# psc3m6 register map
Vendor: Infineon Technologies; Series: PSC3M6; File version: 1.0
CPU: CM33 r0p1, little endian, MPU, FPU, DSP, VTOR, 3 interrupt priority bits, 167 interrupts
Registers are 32-bit, read-write, reset 0x0 unless marked. A register's access mark holds for its fields unless they carry their own. Offsets are from the block's base; [hi:lo] are bit positions; lines under a group give offsets from that group; {n}, {i} and the like mark numbered series; 'fields as' and 'values as' point back to an identical list; <NAME> marks a mode.

## HPPASS (part 3 of 3) — Top Level of MCPASS IP
Base 0x42B00000
0xB0000 CSG group — Comparator Slope Generator
  {0x0+0x40*j} SLICE[{j}] (j=0..8) group — CSG Slice configuration registers
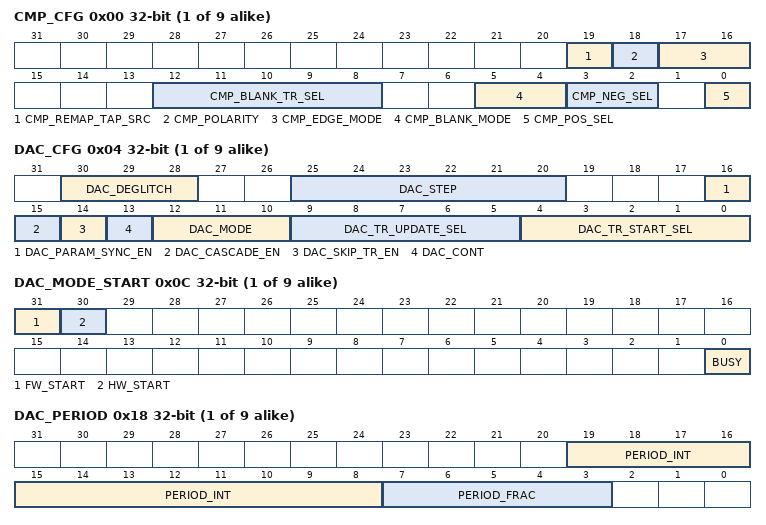
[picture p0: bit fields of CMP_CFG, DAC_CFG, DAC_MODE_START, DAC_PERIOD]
    0x00 CMP_CFG — Comparator Control Register
      [19] CMP_REMAP_TAP_SRC — Choose where to Tap the Remap Source 0: After Glitch Filter 1: After DAC Blanking
      [18] CMP_POLARITY — Comparator Polarity
        0=True (Comparator output is not inverted); 1=INV (Comparator output is inverted)
      [17:16] CMP_EDGE_MODE — Comparator signal mode for Interrupt generation and AC status
        0=DISABLE (Disabled, no interrupts will be asserted); 1=RISING (Rising edge); 2=FALLING (Falling edge); 3=BOTH (Both rising and falling edges)
      [12:8] CMP_BLANK_TR_SEL — Comparator Blank Trigger Select. Select one of the available input MCPASS HW/FW LEVEL mode triggers.
        0=DISABLED (N/A); {v}=TR{v-1} (N/A) (v=1..16)
      [5:4] CMP_BLANK_MODE — Comparator Blanking Mode. Select a level input trigger from CMP_BLANK_TR_SEL to gate the comparators output of this slice to 0. Polarity of active signal is selectable.
        0=DISABLED (Comparator output is not gated. Edge based blanking is enabled. Please see CSG_GROUP_CFG for more information on Edge Based Blanking.); 1=GATE_ON_ONE (Comparator output is gated to 0 by a '1' level trigger. Edge based blanking is disabled.); 2=GATE_ON_ZERO (Comparator output is gated to 0 by a '0' level trigger. Edge based blanking is disabled.)
      [3:2] CMP_NEG_SEL — Comparator Negative Input Select (Select positive input from CMP_POS_SEL)
        0=DAC (DAC is negative input); 1=RSVD_1 (N/A); 2=AIN_NA (Analog input NA); 3=AIN_NB (Analog input NB)
      [0] CMP_POS_SEL — Comparator Positive Input Select (Select negative input from CMP_NEG_SEL)
        0=AIN_PA (Analog input PA); 1=AIN_PB (Analog input PB AN_B[0] etc)
    0x04 DAC_CFG — DAC Control Register
      [30:28] DAC_DEGLITCH — DAC Deglitch Configuration. Default is disabled. If enabled, on any DAC value update,the CMP output is latched in it's current state for the number of cycles indicated.
        0=DISABLED (N/A); 1=ONE_CYCLE (N/A); 2=TWO_CYCLES (N/A); 3=THREE_CYCLES (N/A); 4=FOUR_CYCLES (N/A); 5=FIVE_CYCLES (N/A); 6=SIX_CYCLES (N/A); 7=SEVEN_CYCLES (N/A)
      [25:20] DAC_STEP — Static value of 6 bit DAC step size. Step size is DAC_STEP +1 (default is '1') , range is 1 - 64, only valid in SLOPE/LUT modes. NOTE: In LUT mode each step jumps to a new LUT value on WORD boundaries. So for example: DAC_STEP = 0 (default Step size of 1) advances the LUT address by 4 (LUT WORD boundary) DAC_STEP = 1 (Step size of 2) advances the LUT address by 8, etc
      [16] DAC_PARAM_SYNC_EN — Parameter Sync Enable. 0: Disabled. Always update parameters on DAC trigger (as defined by DAC_MODE) 1: Enabled. Only update parameters on DAC trigger if DAC_PARAM_SYNC.READY is set.
      [15] DAC_CASCADE_EN — Cascade Enable. Synchronize parameter update with previous CSG slice in the case of multi-phase operation. 0: Disabled. 1: Enabled. This CSG updates it's parameters on a DAC trigger only after the previous numbered CSG has updated it's parameters.
      [14] DAC_SKIP_TR_EN — Skip the first DAC hardware update trigger afer a mode is enabled. Allows for a minimum of a full trigger period before the first hardware update occurs. This bit should only be set before operations begin. It should remain set during operation as well. 0: First trigger following DAC_MODE_EN updates the DAC value. 1: First trigger following DAC_MODE_EN is skipped. Following trigger updates the DAC value.
      [13] DAC_CONT — DAC Continuous Mode (Only valid for Slope and LUT modes) 0: Slope/LUT operation is One-Shot, last output value is held 1: Slope/LUT operation is Continuous, operation is restarted when end value is reached
      [12:10] DAC_MODE — DAC Operating Mode. This setting may only be changed when the mode is disabled. See DAC_MODE_START.
        0=BUFFERED (Single Value Buffered Mode); 1=HYSTERETIC (Two Value Hysteretic Buffered Mode); 2=SLOPE_RISING (Rising Slope Mode); 3=SLOPE_FALLING (Falling Slope Mode); 4=SLOPE_TRIANGULAR (Triangular Slope Mode); 5=LUT_FORWARD (LUT Forward Mode); 6=LUT_REVERSE (LUT Reverse Mode); 7=LUT_FWD_REV (LUT Forward Reverse Mode)
      [9:5] DAC_TR_UPDATE_SEL — DAC Trigger Update Select. Select one of the triggers or internal events. See DAC_MODE for detailed operation. If one of the MCPASS HW or FW triggers are selected (see INFRA), then the trigger must be PULSE mode. In addition, the maximum frequency of the active trigger edge must be less than or equal to CSG CLOCK/2 (every other clock).
        0=DISABLED (N/A); 1=TR0 (HW (or FW) input triggers); {v}=TR{v-1} (N/A) (v=2..8); 9=TR8 (HW (or FW) input triggers); {v}=TR{v-1} (N/A) (v=10..16); 17=AC (AC trigger); 18=DAC_PERIOD_TC (Period terminal count. Period divider value is programmed in DAC_PERIOD register); 19=CMP_LEVEL (Use comparator output as Update Trigger: (Used only in Hysteretic Mode ) With DAC_VAL_A as high threshold and DAC_VAL_B as low threshold, CMP 0 to 1 transition (voltage high) outputs DAC_VAL_B ...); 20=CMP_LEVEL_INV (Use inverted comparator output as Update Trigger (Used only in Hysteretic Mode ) (e.g. in the case CMP_POLARITY is set))
      [4:0] DAC_TR_START_SEL — DAC Trigger Start Select. Select one of the MCPASS HW or FW triggers. Trigger must be PULSE mode (see INFRA). See DAC_MODE_START register to select this as the DAC start trigger.
        0=DISABLED (N/A); 1=TR0 (HW (or FW) input triggers); {v}=TR{v-1} (N/A) (v=2..16); 17=AC (AC trigger)
    0x08 DAC_PARAM_SYNC — DAC Parameter Synchronized Update
      [0] READY write-1-sets — Use this bit to synchronize the update of multiple DAC parameters. If DAC_PARAM_SYNC_EN bit is '1', then set this bit after writes to all parameter registers (VAL_A, VAL_B, DAC_PERIOD, DAC_STEP) are complete to synchronize parameter update on a subsequent DAC trigger This allows for writes to multiple registers to be written before new parameters are updated to avoid partial updates. This bit is cleared by HW on the parameter update event. if DAC_PARAM_SYNC_EN is '0', this bit is ignored and parameters are updated on the following UPDATE trigger. NOTE: This bit can be used in conjunction with DAC_CASCADE_EN to synchronize the parameter update of multiple CSG slices.
    0x0C DAC_MODE_START
      [31] FW_START — 1: Starts the selected mode on this FW write. 0: Stops the selected mode. When this bit is cleared, the current DAC_VAL will not change unless it is over-written directly - or a new DAC mode is started. This field is automatically reset to '0' on DAC_SLOPE_DONE event (unless DAC_CONT is set for continous mode).
      [30] HW_START — 1: Wait for subsequent DAC_START_TR to start the selected mode. 0: Stops the selected mode. When this bit is cleared, the current DAC_VAL will not change unless it is over-written directly - or a new DAC mode is started. This field is automatically reset to '0' on DAC_SLOPE_DONE event (unless DAC_CONT is set for continous mode).
      [0] BUSY ro — Read only bit to indicate that a DAC MODE has been enabled and is currently in progress. If FW_START is used to start the mode, then the FW_START bit is equivalent to this bit and low when the mode is completed or stopped. If HW_START is used to start the mode, then this status bit goes high on the DAC_START_TR event, and low when the mode is completed or stopped. NOTE: This read only bit refects the state of the DAC controller which is reset in DeepSleep and therefore this bit is not a retention bit.
    0x10 DAC_VAL_A — DAC Vaue A Buffer
      [9:0] VALUE — DAC A Value, usage is mode dependent (see DAC_MODE) NOTE: In LUT modes this is the Start Address of the LUT waveform in byte address format (e.g. 0, 4, 8, ... 1F8, 1FC)
    0x14 DAC_VAL_B — DAC Value B Buffer
      [9:0] VALUE — DAC B Value, usage is mode dependent (see DAC_MODE) NOTE: In LUT modes this is the End Address of the LUT waveform in byte address format (e.g. 0, 4, 8, ... 1F8, 1FC)
    0x18 DAC_PERIOD — DAC Period Buffer
      [19:8] PERIOD_INT — 12-bit Integer Divide Value. Integer count by (1+PERIOD_INT). Allows for integer counts in the range [1, 4096].
      [7:3] PERIOD_FRAC — 5-bit Fractional Divide Value. Allows for fractional count in the range [0, 31/32]
    0x1C DAC_VAL — DAC FW write
      [9:0] VALUE — Direct drive to DAC Hard IP for output. When DAC_MODE_EN is '0', the value in this register is output. A write to this register also STOPs the current DAC_MODE operation, and subsequent DAC triggers are ignored.
    0x20 DAC_STATUS ro — Read of Current DAC Value
      [9:0] DAC_VAL — Read Only value of current digital DAC output
    0x24 CMP_STATUS ro — Read of Comparator Value
      [0] CMP_VAL — Read Only value of comparator output
  {0x400+0x200*j} LUT_CFG[{j}] (j=0..2) group — DAC LUT waveform data
    {0x0+4k} LUT_DATA[{k}] (k=0..127) reset not defined — LUT Waveform Data
      [9:0] DATA — DAC waveform
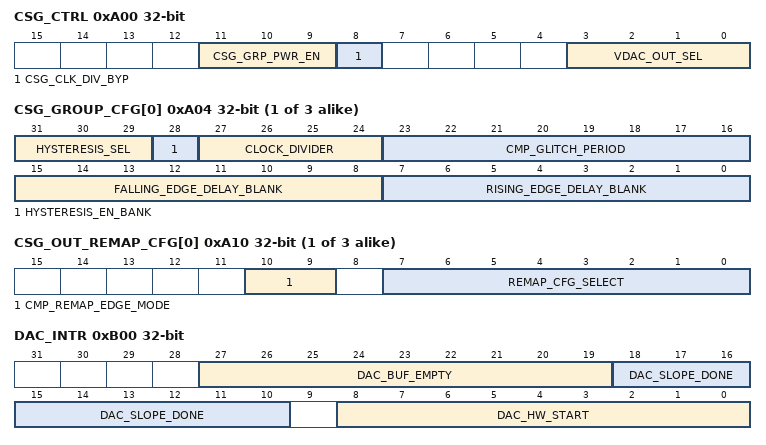
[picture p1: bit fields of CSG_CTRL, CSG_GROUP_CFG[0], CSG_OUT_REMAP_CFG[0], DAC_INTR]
  0xA00 CSG_CTRL — CSG control register
    [11:9] CSG_GRP_PWR_EN — Individual Group Power Enables. 0: Slices 0-2 1: Slices 3-5 2: Slices 6-8
    [8] CSG_CLK_DIV_BYP
    [3:0] VDAC_OUT_SEL — Select the DAC output for SAR conversion
      0=DISABLED (Hi-Z (Disabled)); {v}=DAC{v-1} (Connect DAC{v-1} to ADC input) (v=1..9)
  {0xA04+4j} CSG_GROUP_CFG[{j}] (j=0..2) — CSG Group Configuration Register
    [31:29] HYSTERESIS_SEL — Hysteresis magnitude selection
      0=HYST_0MV (0 mV); 1=HYST_12MV (12 mV); 2=HYST_24MV (24 mV); 3=HYST_36MV (36 mV); 4=HYST_48MV (48 mV); 5=HYST_60MV (60 mV); 6=HYST_72MV (72 mV); 7=HYST_84MV (84mV)
    [28] HYSTERESIS_EN_BANK — Enable the Hysteresis in Bank of CSGs 0x0 - disabled Hysteresis 0x1 - enable Hysteresis
    [27:24] CLOCK_DIVIDER — Comparator Blank Clock Divider. To add more range to the blanking period, the clock can be divided.
      0=DIV_1 (N/A); 1=DIV_2 (N/A); 2=DIV_4 (N/A); 3=DIV_8 (N/A); 4=DIV_16 (N/A); 5=DIV_32 (N/A); 6=DIV_64 (N/A); 7=DIV_128 (N/A); 8=DIV_256 (N/A); 9=DIV_512 (N/A); 10=DIV_1024 (N/A); 11=DIV_2048 (N/A)
    [23:16] CMP_GLITCH_PERIOD — Comparator Glitch Width Count. Choose the number of output values equal to 0x1 in series to achieve an output filter of 0x1. This number also reflects the number of output value equal to 0x0 in series to achieve a an output filter of 0x0.
    [15:8] FALLING_EDGE_DELAY_BLANK — Comparator Blank Clock Period. Choose the number of clock periods to blank starting at the negative edge of the Level Trigger. This is scaled by the Comparator Blank Clock Divider. 0 - 255 - Clock Period selection
    [7:0] RISING_EDGE_DELAY_BLANK — Comparator Blank Clock Period. Choose the number of clock periods to blank starting at the positive edge of the Level Trigger. This is scaled by the Comparator Blank Clock Divider. 0 - 255 - Clock Period selection
  {0xA10+4j} CSG_OUT_REMAP_CFG[{j}] (j=0..2) — CSG Output Remap Configuration
    [10:9] CMP_REMAP_EDGE_MODE — Comparator signal mode for Interrupt generation and AC status
      0=DISABLE (edge detection disabled. Interrupt disabled); 1=RISING (Rising edge); 2=FALLING (Falling edge); 3=BOTH (Both rising and falling edges)
    [7:0] REMAP_CFG_SELECT — Remap CSG Output Logical Translation. The CSG Comparator outputs act as the control bits of an 8:1 mux. This field is the 8 bits.
  0xB00 DAC_INTR — DAC Interrupt register
    [27:19] DAC_BUF_EMPTY write-1-clears — When BUFFERED or HYSTERETIC mode is enabled, this interrupt is set when there is a DAC UPDATE trigger that transfers the buffered value(s) to active value(s) (see mode operation) and it means that the user may write new values to the buffer registers.
    [18:10] DAC_SLOPE_DONE write-1-clears — When SLOPE or LUT mode is enabled, this interrupt is set when the SLOPE (or LUT waveform) has completed. This interrupt is also set periodically on the last value of a DAC SLOPE in continuous mode
    [8:0] DAC_HW_START write-1-clears — This DAC_MODE operation was started with a HW START trigger.
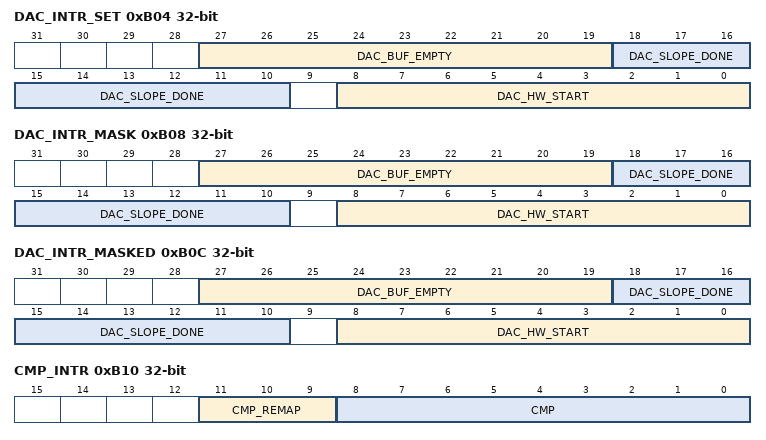
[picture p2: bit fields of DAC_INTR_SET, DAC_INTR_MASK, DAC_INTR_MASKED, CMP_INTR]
  0xB04 DAC_INTR_SET — DAC Interrupt request set register
    [27:19] DAC_BUF_EMPTY write-1-sets — Write with '1' to set corresponding bit in interrupt request register.
    [18:10] DAC_SLOPE_DONE write-1-sets — Write with '1' to set corresponding bit in interrupt request register.
    [8:0] DAC_HW_START write-1-sets — Write with '1' to set corresponding bit in interrupt request register.
  0xB08 DAC_INTR_MASK — DAC Interrupt request mask
    [27:19] DAC_BUF_EMPTY — Mask bit for corresponding bit in interrupt request register.
    [18:10] DAC_SLOPE_DONE — Mask bit for corresponding bit in interrupt request register.
    [8:0] DAC_HW_START — Mask bit for corresponding bit in interrupt request register.
  0xB0C DAC_INTR_MASKED ro — DAC Interrupt request masked
    [27:19] DAC_BUF_EMPTY — Logical and of corresponding request and mask bits.
    [18:10] DAC_SLOPE_DONE — Logical and of corresponding request and mask bits.
    [8:0] DAC_HW_START — Logical and of corresponding request and mask bits.
  0xB10 CMP_INTR — CMP Interrupt register
    [11:9] CMP_REMAP write-1-clears — This CMP_REMAP(n) state has generated an interrupt request (see CSG_SLICE.CSG_OUT_REMAP_CFG.CMP_REMAP_EDGE_MODE)
    [8:0] CMP write-1-clears — This CMP(n) state has generated an interrupt request (see CSG_SLICE.CMP_CFG.CMP_EDGE_MODE)
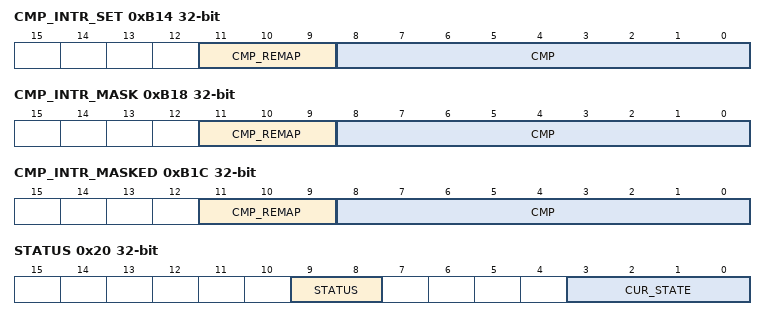
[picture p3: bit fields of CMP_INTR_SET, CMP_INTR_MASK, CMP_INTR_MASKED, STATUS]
  0xB14 CMP_INTR_SET — CMP Interrupt request set register
    [11:9] CMP_REMAP write-1-sets — Write with '1' to set corresponding bit in interrupt request register.
    [8:0] CMP write-1-sets — Write with '1' to set corresponding bit in interrupt request register.
  0xB18 CMP_INTR_MASK — CMP Interrupt request mask
    [11:9] CMP_REMAP — Mask bit for corresponding bit in interrupt request register.
    [8:0] CMP — Mask bit for corresponding bit in interrupt request register.
  0xB1C CMP_INTR_MASKED ro — CMP Interrupt request masked
    [11:9] CMP_REMAP — Logical and of corresponding request and mask bits.
    [8:0] CMP — Logical and of corresponding request and mask bits.
  0xB20 VDAC_OUT_BLANK — Blanking control for DAC Observability
    [4:0] BLANK_CNT — This field enables blanking iin CLK_CSG cycles of the Comparator output when one of the DACs in a CSG SLICE is connected as an input for SAR conversion (See CTRL.VDAC_OUT_SEL) Disabled: BLANK_CNT = 0 Enabled : BLANK_CNT is between 1 and 31 When the DAC output is first connected to the SAR sampler input, the DAC may have a short transient (50ns). If the DAC is also an active input to the Comparator, this transient may cause false transitions on the Comparator output. To mitigate this, the Comparator output is latched for the duration of the BLANK_CNT value. This 5-bit value is the number of clock cycles to blank (latch) the Comparator output. This count is in CLK_CSG cycles as programmed in the MXPERI divider. The recommended value is 50ns blanking. Examples are: CLK_CSG @40MHz, use 2 cycles CLK_CSG @80MHz, use 4 cycles CLK_CSG @120MHz, use 8 cycles
  0xB30 CSG_SYNC — CSG Sync Enable register
    [0] SYNC_EN — Risk Mitigation only. By default the CSG Hard IP and comparator output is synchronous to CLK_CSG. When this bit is set to '1', the CSG comparator output is double synced.
  {0xB40+4j} CSG_AROUTEMUX_SEL[{j}] (j=0..8) — CSG AROUTE Mux Select Bits
    [3:0] AROUTE_SEL — Aroute Mux Select. Its 4:1 Mux with 1-hot select
      1=AIN_A (Analog input A (each Mux is defined in SAS)); 2=AIN_B (Analog input B (each Mux is defined in SAS)); 4=AIN_C (Analog input C (each Mux is defined in SAS)); 8=AIN_D (Analog input D (each Mux is defined in SAS))
0xD0000 ACTRLR group — Autonomnous Controller
  0x00 CTRL — Control register
    [31] ENABLED — 0: MCPASS IP disabled - All mision logic and status is reset, all analog controls are disabled, all clocking is disabled (only available function is AHB access). NOTE: The SARADC trim is also reset and therefore the SAR needs to be re-calibrated, or previously saved trim values re-written if the IP is disabled. The only functioing system is the AHB register access when the IP is disabled. 1: MCPASS IP enabled. Clocks ungated, Reset negated
  0x04 CMD_RUN — Run Command register
    [0] RUN write-1-sets — When firmware writes a '1' here it will trigger the Autonomous Controller to run, hardware clears this bit when the Autonomous Controller acknowledges the run command. This command has no action if the Autonomous Controller is already running. When the AC is stopped, the AC may be set back into running state by setting the CMD STATE to the address ofone ore more instructions and by setting this RUN bit to '1'
  0x08 CMD_STATE — State Override register
    [3:0] STATE — Autonomous Controller CMD_STATE register. This register indicates which instruction the AC will start execution from when it receives a RUN command. Software can overrwrite this field only when STATUS.STATUS=STOPPED to set the AC to execute from a specific STATE when triggered by the RUN command. When first enabled, this register is reset to 0, so by default the AC starts executing at state 0.
  0x10 BLOCK_STATUS ro — Block Ready status register
    [0] READY — This bit reflects the AC BLOCK_READY condition, which can be polled by SW to determine if all the enabled blocks have settled and are ready for use
  0x20 STATUS ro — AC Status register
    [9:8] STATUS — This field indicates if the Autonomous Controller is busy
      0=STOPPED (Autonomous Controller is stopped); 1=RUNNING (Autonomous Controller is running); 2=RSVD2 (N/A); 3=RSVD3 (N/A)
    [3:0] CUR_STATE — This register indicates where in memory the AC is currently executing instructions.
  0x24 CFG — AC Config register
    [4:0] DOUT_EN — DOUT_EN controls the GPIO output drive mode though the HSIOM This register enables the DOUT feature, where up to 5 GPIOs can be controlled programatically with the AC (ACTRLR.TIMER_TABLE.TT_CFG0.DOUT). To use this feature: 1) The HSIOM (High Speed I/O Mux) device configuration must be set to select one or more DOUT/DOUT_EN bits to drive the associated GPIOs. 2) The associated bit(s) in this register must be set to enable the GPIO for output drive mode. 0 :DOUT[n] GPIO output disabled 1: DOUT[n] GPIO output enabled
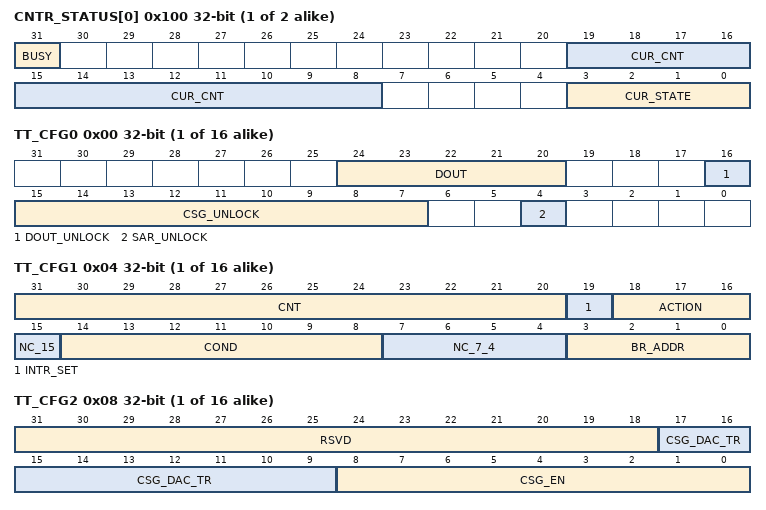
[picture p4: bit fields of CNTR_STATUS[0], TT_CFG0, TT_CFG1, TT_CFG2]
  {0x100+4j} CNTR_STATUS[{j}] (j=0..1) ro — Loop/Interval counter status register
    [31] BUSY — This field indicates if the counter is busy
    [19:8] CUR_CNT — This field indicates the count value for the given counter.
    [3:0] CUR_STATE — This field indicates which Timer Table State the counter is assigned. Valid numbers are 0-15
  {0x800+0x10*j} TTCFG[{j}] (j=0..15) group — Timer Table Structure
    0x00 TT_CFG0 — AC Configuration 0
      [24:20] DOUT — MCPASS data out generation When this function is enabled (see ACTRLR.CFG.DOUT_EN), any enabled bits in this field will be driven through HSIOM to the associated GPIO pads for output. This allows the AC to digital control to an off chip resource (e.g. enable a sensor) as part of AC programming.
      [16] DOUT_UNLOCK — DOUT Unlock 0: Lock: DOUT does NOT get updated 1: Unlock: DOUT does get updated
      [15:7] CSG_UNLOCK — CSG Unlock 0: Lock: CSG fields: EN does NOT get updated 1: Unlock: CSG fields: EN does get updated
      [4] SAR_UNLOCK — SAR Unlock 0: Lock: SAR fields: EN does NOT get updated 1: Unlock: SAR fields: EN does get updated These fields are used to prevent unintentional mode transitions. For example, when you wish to enable the SAR, you set this SAR_UNLOCK bit to '1' in that state. As other states will have a '0' for this field, and therefore the SAR_EN will not be inadvertantly be set to '0' in other states. If you want to disable the SAR, set this SAR_UNLOCK bit to '1' again and the SAR_EN to '0' for the disable to take effect.
    0x04 TT_CFG1 reset not defined — AC Configuration 1
      [31:20] CNT — This field is used to set the timer/counter values for either interval and loop counts. The actual count is CNT value + 1. Therefore, the range is 1 to 4096. The value of 1 is degenerate.
      [19] INTR_SET — AC Interrupt Set. This will generate a CPU interrupt or Hardware Trigger output if configured. If ACTION=WAIT_FOR, the interrupt is generated after the COND occurs. The AC Interrupt may be configured in MCPASS_MMIO.MCPASS_INTR. The AC Hardware trigger may be configured in MCPASS_MMIO.TR_PULSE_OUT
      [18:16] ACTION — Autonomous Controller Action
        0=STOP (Stop the autonomous controller); 1=NEXT (Execute the current state and proceed to the next state); 2=WAIT_FOR (Wait for the associated COND to occur before moving to the next state If COND=FALSE, stay in the present state indefinitely. If COND=TRUE, move to the next state.); 3=BRANCH_IF_TRUE (Check if COND has occurred, If it has, take the indicated branch (BR ADDR), if not, proceed to the next state. If COND=FALSE, proceed to the next state. If COND=TRUE, take the indicated branch (BR_ADDR).); 4=BRANCH_IF_FALSE (Check if COND has occurred, If it has proceed to the next state, if not, take the indicated branch (BR ADDR) If COND=FALSE, take the indicated branch (BR_ADDR). If COND=TRUE, proceed to the next state.); 5=RSVD_0 (N/A); 6=RSVD_1 (N/A); 7=RSVD_2 (N/A)
      [15] NC_15
      [14:8] COND — Autonomous Controller Condition
      [7:4] NC_7_4
      [3:0] BR_ADDR — Absolute address of the branch if taken (0-15 possible)
    0x08 TT_CFG2 reset not defined — AC Configuration 2
      [31:18] RSVD
      [17:9] CSG_DAC_TR — CSG Slice Triggers. After the block is ready for use - these bits may be used for CSG DAC START and UPDATE triggers. The type of trigger is programmed in the CSG_SLICE register block. If ACTION=WAIT_FOR, the trigger always occurs in the fir cycle of that state
      [8:0] CSG_EN — CSG Slice Enables. The CSG UNLOCK bits must be set in the same state as these bits (see TT_CFG0) to enable or disable. These bits are normally used in conjunction with ACTION=WAIT_FOR and COND=BLOCK_READY
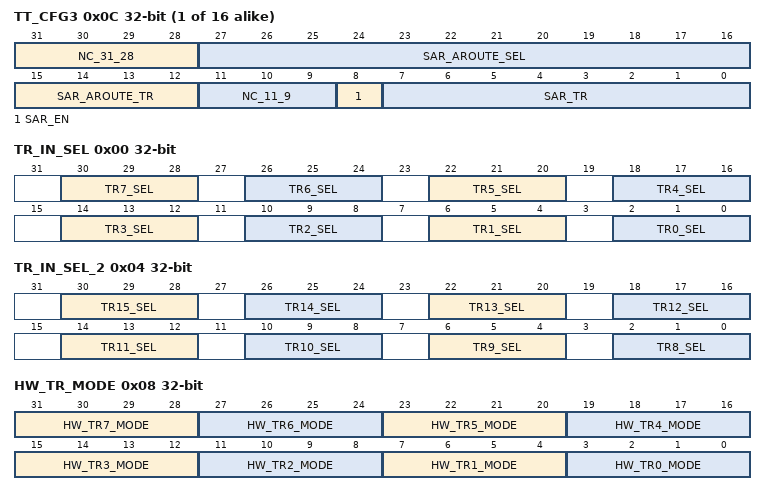
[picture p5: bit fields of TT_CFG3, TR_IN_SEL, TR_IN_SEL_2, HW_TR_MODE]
    0x0C TT_CFG3 reset not defined — AC Configuration 3
      [31:28] NC_31_28
      [27:16] SAR_AROUTE_SEL — SAR Route setting (3 bits per mux) to select the routing input. The routing bits in this field are only valid if the associated SAR_ROUTE_TR is set.
      [15:12] SAR_AROUTE_TR — SAR Aroute Trigger (1 bit per mux) to change Route setting for one or more AROUTE MUXes. Set this bit in conjuction with a new SAR_AROUTE_SEL value.
      [11:9] NC_11_9
      [8] SAR_EN — SARADC Enable The SAR UNLOCK bit must be set in the same state as this bit (see TT_CFG0) to enable or disable. This bit is normally used in conjunction with ACTION=WAIT_FOR and COND=BLOCK_READY
      [7:0] SAR_TR — SAR Table Entry Triggers. After the block is ready for use - these bits may be used to trigger one ore more SAR Entries. If ACTION=WAIT_FOR, the trigger always occurs in the fir cycle of that state
0xE0000 INFRA group — MCPASS infrastructure
  0x00 TR_IN_SEL — Trigger Input Select Triggers 0-7
    [4n+2:4n] TR{n}_SEL (n=1..7)
    [2:0] TR0_SEL — Trigger selection. NOTE: ALL TRIGGERS ARE GATED (DISABLED) BY HARDWARE UNTIL BLOCK READY IS '1'
      0=DISABLED (Trigger is off); 1=HW_TR_A (Select an external HW trigger from A trigger inputs. For additional options see HW_TR_MODE); 2=HW_TR_B (Select the external HW trigger from B trigger inputs. For additional options see HW_TR_MODE); 3=FW_PULSE (Select FW PULSE trigger. See FW_TR_IN_PULSE.); 4=FW_LEVEL (Select FW LEVEL trigger. See FW_TR_IN_LEVEL.)
  0x04 TR_IN_SEL_2 — Trigger Input Select Triggers 8-15
    [4n-30:4n-32] TR{n}_SEL (n=9..15)
    [2:0] TR8_SEL — Trigger selection. NOTE: ALL TRIGGERS ARE GATED (DISABLED) BY HARDWARE UNTIL BLOCK READY IS '1'
      values as INFRA.TR_IN_SEL.TR0_SEL
  0x08 HW_TR_MODE — HW Trigger Mode Triggers 0-7
    [4n+3:4n] HW_TR{n}_MODE (n=1..7)
    [3:0] HW_TR0_MODE — If HW trigger is selected, this controls the trigger mode.
      0=PULSE_ON_POS_DOUBLE_SYNC (HW trigger is assumed to be async in FC, it is double synced and converted to pulse on positive edge.); 1=PULSE_ON_NEG_DOUBLE_SYNC (HW trigger is assumed to be async in FC, it is double synced and converted to synchronous pulse on negative edge.); 2=PULSE_ON_BOTH_DOUBLE_SYNC (HW trigger is assumed to be async in FC, it is double synced and converted to synchronous pulse on both edges.); 3=LEVEL_DOUBLE_SYNC (HW trigger is assumed to be async in FC, it is double synced and used as a level trigger. NOTE: Level trigger selection is only for use by a CSG Slice in Hyteretic Mode and the minimum duration of the high or low level must be greater than or equal to the CSG clock period.); 4=PULSE_ON_POS_SINGLE_SYNC (HW trigger is assumed to sync in FC, captured in a register, and then converted to pulse on positive edge); 5=PULSE_ON_NEG_SINGLE_SYNC (HW trigger is assumed to sync in FC, captured in a register, and then converted to pulse on negative edge); 6=PULSE_ON_BOTH_SINGLE_SYNC (HW trigger is assumed to sync in FC, captured in a register, and then converted to pulse on both edges); 7=LEVEL_SINGLE_SYNC (HW trigger is assumed to be async in FC, captured in a register, and used as a level trigger. NOTE: Level trigger selection is only for use by a CSG Slice in Hyteretic Mode and the minimum duration of the high or low level must be greater than or equal to the CSG clock period.)
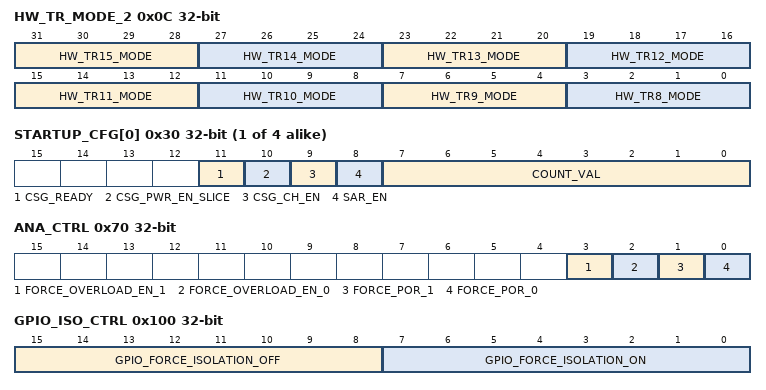
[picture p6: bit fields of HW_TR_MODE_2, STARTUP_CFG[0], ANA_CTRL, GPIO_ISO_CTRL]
  0x0C HW_TR_MODE_2 — HW Trigger Mode Triggers 8-15
    [4n-29:4n-32] HW_TR{n}_MODE (n=9..15)
    [3:0] HW_TR8_MODE — If HW trigger is selected, this controls the trigger mode.
      values as INFRA.HW_TR_MODE.HW_TR0_MODE
  0x10 FW_TR_PULSE — FW Pulse Mode Trigger
    [15:0] FW_TR_PULSE write-1-sets — If FW is selected in TR_IN_SEL, A write of '1' to this register will generate an internal PULSE trigger. These bits will be cleared automatically by HW. Firmware Rule: Poll on ACTRLR.BLOCK_STATUS to become '1' before issuing firmware triggers
  0x14 FW_TR_LEVEL — FW Level Mode Trigger
    [15:0] FW_TR_LEVEL — If FW is selected in TR_IN_SEL, Writes to this register will be passed to the internal trigger as a LEVEL '1' or '0. NOTE: LEVEL mode trigger is only valid for CSG module, Do not use for SAR Entry. Firmware Rule: Poll on ACTRLR.BLOCK_STATUS to become '1' before issuing firmware triggers
  0x20 CLOCK_STARTUP_DIV reset 0x7 — Startup Clock Divder
    [7:0] DIV_VAL — Divide MCPASS a prescaled clock divide to generate block startup delays. Actual divide value is DIV_VAL+1. Typically this register should be set to give a period of 200ns, so the count depends on CLK_HF. NOTE: This counter is clocked on CLK_HF/2 Examples: For CLK_HF = 80MHz (CLK_INFRA = 40MHz), set DIV_VAL to 7 (8 cycles * 25ns = 200ns, default) For CLK_HF = 160MHz (CLK_INFRA = 80MHz) set DIV_VAL to 15 (16 cycles * 12.5ns = 200ns) For CLK_HF = 240MHz (CLK_INFRA = 120MHz) set DIV_VAL to 23 (24 cycles * 8.33ns = 200ns
  {0x30+4j} STARTUP_CFG[{j}] (j=0..3) — Startup configuration
    [11] CSG_READY — CSG Auto Zero/Comparator gate startup When this bit is set, the associated COUNT_VAL must be calculated relative to the CLK_CSG divide and the resulting period must be 33 CLK_CSG periods Examples: Assuming we have 200ns prescale value programmed into CLOCK_STARTUP_DIV.DIV_VAL. With the examples of CLK_CSG as configured by MXPERI at the following frequencies: For CSG at 40 MHz, 25ns x 33 cycles = 825ns. roundup(825/200) = 5 (COUNT_VAL = 4) For CSG at 80 Mhz, 12.5ns x 33 cycles = 412ns roundup(412/200) = 3 (COUNT_VAL = 2) For CSG at 120 MHz, 8.33 ns x 33 cycles = 275ns roundup(275/200) = 2 (COUNT_VAL = 1)
    [10] CSG_PWR_EN_SLICE — CSG Slice Enable startup
    [9] CSG_CH_EN — CSG Channel Enable startup
    [8] SAR_EN — SAR startup
    [7:0] COUNT_VAL — Actual count value is COUNT_VAL+1
  0x50 VDDA_STATUS ro — Analog Voltage Status
    [0] VDDA_OK — Read only status bit to determine the presence of VDDA. This bit is set by HW and it must be 1 prior to enabling the SAR or CSG. 0: VDDA is below minimum threshold 1: VDDA is at or above minimum threhold
  0x70 ANA_CTRL — Analog Control
    [3] FORCE_OVERLOAD_EN_1 — Override for Analog OVERLOAD Hardware circuit 0: (default) OVERLOAD enable is controlled by ACTRL.CTRL.ENABLED bit 1: Force OVERLOAD enable on NOTE: If this bit is set to 1, FORCE_OVERLOAD_EN_0 must be 0
    [2] FORCE_OVERLOAD_EN_0 — Override for Analog OVERLOAD Hardware circuit. 0: (default) OVERLOAD enable is controlled by ACTRL.CTRL.ENABLED bit 1: Force OVERLOAD enable off NOTE: If this bit is set to 1, FORCE_OVERLOAD_EN_1 must be 0
    [1] FORCE_POR_1 — Override for Analog POR Hardware circuit. 0: (default) POR is controlled by analog hardware 1: Force POR negated (POR is an active low signal) NOTE: If this bit is set to 1, FORCE_POR_0 must be 0.
    [0] FORCE_POR_0 — Override for Analog POR Hardware circuit. 0: (default) POR is controlled by analog hardware 1: Force POR asserted (POR is an active low signal) If the MCPASS is not in use, set this bit to '1' to achieve the lowest level of IP leakage NOTE: If this bit is set to 1, FORCE_POR_1 must be 0.
  0x100 GPIO_ISO_CTRL — GPIO Isolation Controls
    [15:8] GPIO_FORCE_ISOLATION_OFF — Force the Isolation signal OFF for GPIO. A value of 1 indicates the isolation switch is open and the output is NOT connected to the input.
    [7:0] GPIO_FORCE_ISOLATION_ON — Force the Isolation signal to 'Connected' for GPIO. A value of 1 indicates the isolation switch is closed and the output is connected to the input.
  0xE00 AREFV2 group — AREF Configuration
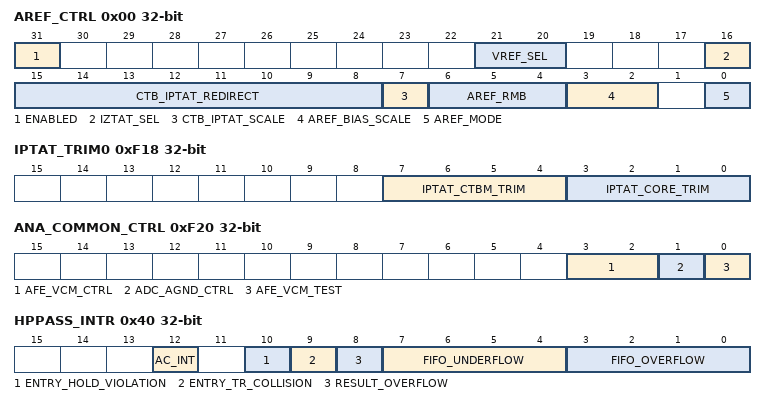
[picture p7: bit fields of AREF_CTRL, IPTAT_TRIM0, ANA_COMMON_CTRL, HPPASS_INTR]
    0x00 AREF_CTRL — AREF control
      [31] ENABLED — - 0: AREF disabled - 1: AREF enabled
      [21:20] VREF_SEL
        0=RSVD (N/A); 1=LOCAL (Use locally generated Vref); 2=EXTERNAL (Use externally supplied Vref (aref_ext_vref))
      [16] IZTAT_SEL
        0=RSVD (N/A); 1=LOCAL (Use locally generated 250nA)
      [15:8] CTB_IPTAT_REDIRECT
      [7] CTB_IPTAT_SCALE
      [6:4] AREF_RMB
      [3:2] AREF_BIAS_SCALE
      [0] AREF_MODE
  0xF00 VREF_TRIM0 — VREF Trim bits
    [7:0] VREF_ABS_TRIM
  0xF04 VREF_TRIM1 — VREF Trim bits
    [7:0] VREF_TEMPCO_TRIM
  0xF08 VREF_TRIM2 — VREF Trim bits
    [7:0] VREF_CURV_TRIM
  0xF0C VREF_TRIM3 — VREF Trim bits
    [3:0] VREF_ATTEN_TRIM — Obsolete
  0xF10 IZTAT_TRIM0 — IZTAT Trim bits
    [7:0] IZTAT_ABS_TRIM
  0xF14 IZTAT_TRIM1 — IZTAT Trim bits
    [7:0] IZTAT_TC_TRIM — IZTAT temperature correction trim (RMB) 0x00 : No IZTAT temperature correction 0xFF : Maximum IZTAT temperature correction As this is a Risk Mitigation Register, it should be loaded with 0x08.
  0xF18 IPTAT_TRIM0 — IPTAT Trim bits
    [7:4] IPTAT_CTBM_TRIM — CTMB PTAT Current Trim 0x0 : Minimum CTMB IPTAT Current (~875nA) 0xF : Maximum CTMB IPTAT Current (~1.1uA)
    [3:0] IPTAT_CORE_TRIM — IPTAT trim 0x0 : Minimum IPTAT current (~150nA at room) 0xF : Maximum IPTAT current (~350nA at room)
  0xF1C ICTAT_TRIM0 — ICTAT Trim bits
    [3:0] ICTAT_TRIM — ICTAT trim 0x00 : Minimum ICTAT current (~150nA at room) 0x0F : Maximum ICTAT current (~350nA at room)
  0xF20 ANA_COMMON_CTRL — AFE Common Control
    [3:2] AFE_VCM_CTRL — Bit 0 controls vddq switch and bit 1 controls varef switch <00> - VCM gen block off, outputs vssa <01> - VCM gen block connects to vdda and outputs vdda/2 <10> - VCM gen block connects to varef_ext and outputs varef_ext/2
    [1] ADC_AGND_CTRL — 0x0 - AGND, 0x1 uses AN_A4 as ADC ground
    [0] AFE_VCM_TEST — AFE VCM Test mode control 0: AFE VCM voltage is not sent to test bus 1:AFE VCM voltage is sent to test bus
0xF0000 MMIO group — MCPASS top-level MMIO
  0x00 FIFO_INTR ro — FIFO Interrupt request register
    [3:0] FIFO_LEVEL — This field will be '1', when STATUS.USED >= CTRL.LEVEL+1 and '0' when STATUS.USED < CTRL.LEVEL+1 for the indicated FIFO. This interrupt is level based.
  0x10 FIFO_INTR_SET — FIFO Interrupt set request register
    [3:0] FIFO_LEVEL_SET — Write with '1' to set corresponding bit in interrupt request register. Write with '0' to clear corresponding bit in interrupt request register. NOTE: This register has different functionality than normal event based interrupt register as this interrupt is LEVEL based
  0x20 FIFO_INTR_MASK — FIFO Interrupt mask register
    [3:0] FIFO_LEVEL_MASK — Mask bit for corresponding bit in interrupt request register.
  0x30 FIFO_INTR_MASKED ro — FIFO Interrupt masked request register
    [3:0] FIFO_LEVEL_MASKED — Logical and of corresponding request and mask bits.
  0x40 HPPASS_INTR — MCPASS Interrupt request register
    [12] AC_INT write-1-clears — HW sets this field to '1', when the AC generates a programmed interrupt. Write with '1' to clear bit.
    [10] ENTRY_HOLD_VIOLATION write-1-clears — HW sets this bit if the samplers in a SAR Entry are in HOLD state longer than the programmed count value . Write a '1' to clear this bit.
    [9] ENTRY_TR_COLLISION write-1-clears — HW sets this bit if a SAR Entry trigger is asserted while that Entry is in progress, from triggering until conversion is complete. Write a '1' to clear this bit.
    [8] RESULT_OVERFLOW write-1-clears — HW sets this field to '1 on RESULT overflow. This bit is set when new SAR Entry or FIR results are written and the associated bit the the INTR_SAR_RESULT register bit is set, implying the previous results have not been read. To determine which Entry or FIR results caused this see SAR_CFG/RESULT_OVERFLOW. Write a '1' to clear this bit.
    [7:4] FIFO_UNDERFLOW write-1-clears — HW sets this field to '1', when reading from an empty FIFO.. See FIFO_CFG/STATUS (read and write pointers) and FIFO_CFG/USED register for detailed infomration. Write with '1' to clear bit.
    [3:0] FIFO_OVERFLOW write-1-clears — HW sets this field to '1', when writing to a full FIFO. See FIFO_CFG/STATUS (read and write pointers) and FIFO_CFG/USED register for detailed infomration. Write with '1' to clear bit.
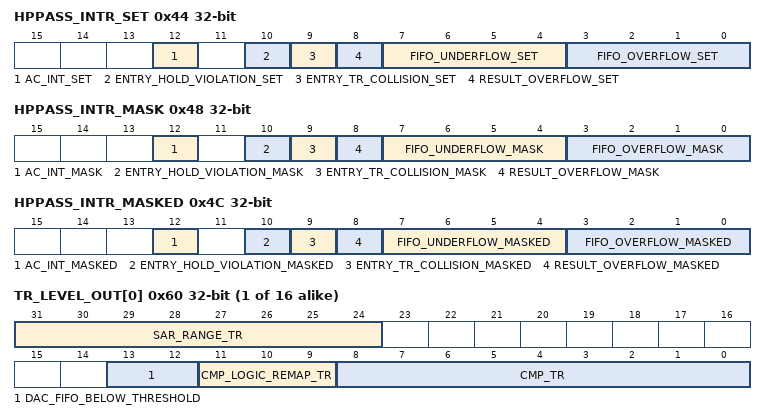
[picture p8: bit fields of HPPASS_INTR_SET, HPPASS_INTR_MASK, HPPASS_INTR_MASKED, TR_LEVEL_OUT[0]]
  0x44 HPPASS_INTR_SET — MCPASS Interrupt set request register
    [12] AC_INT_SET write-1-sets — Write with '1' to set corresponding bit in interrupt request register. (a write of '0' has no effect).
    [10] ENTRY_HOLD_VIOLATION_SET write-1-sets — Write with '1' to set corresponding bit in interrupt request register. (a write of '0' has no effect).
    [9] ENTRY_TR_COLLISION_SET write-1-sets — Write with '1' to set corresponding bit in interrupt request register. (a write of '0' has no effect).
    [8] RESULT_OVERFLOW_SET write-1-sets — Write with '1' to set corresponding bit in interrupt request register. (a write of '0' has no effect).
    [7:4] FIFO_UNDERFLOW_SET write-1-sets — Write with '1' to set corresponding bit in interrupt request register. (a write of '0' has no effect).
    [3:0] FIFO_OVERFLOW_SET write-1-sets — Write with '1' to set corresponding bit in interrupt request register. (a write of '0' has no effect).
  0x48 HPPASS_INTR_MASK — MCPASS Interrupt mask register
    [12] AC_INT_MASK — Mask bit for corresponding bit in interrupt request register.
    [10] ENTRY_HOLD_VIOLATION_MASK — Mask bit for corresponding bit in interrupt request register.
    [9] ENTRY_TR_COLLISION_MASK — Mask bit for corresponding bit in interrupt request register.
    [8] RESULT_OVERFLOW_MASK — Mask bit for corresponding bit in interrupt request register.
    [7:4] FIFO_UNDERFLOW_MASK — Mask bit for corresponding bit in interrupt request register.
    [3:0] FIFO_OVERFLOW_MASK — Mask bit for corresponding bit in interrupt request register.
  0x4C HPPASS_INTR_MASKED ro — MCPASS Interrupt masked request register
    [12] AC_INT_MASKED — Logical and of corresponding request and mask bits.
    [10] ENTRY_HOLD_VIOLATION_MASKED — Logical and of corresponding request and mask bits.
    [9] ENTRY_TR_COLLISION_MASKED — Logical and of corresponding request and mask bits.
    [8] RESULT_OVERFLOW_MASKED — Logical and of corresponding request and mask bits.
    [7:4] FIFO_UNDERFLOW_MASKED — Logical and of corresponding request and mask bits.
    [3:0] FIFO_OVERFLOW_MASKED — Logical and of corresponding request and mask bits.
  0x50 TR_LEVEL_CFG — LEVEL Trigger out configuration
    [15:0] BYPASS_SYNC — When this bit is set, the output flip-flop for the given TR_LEVEL_OUT is bypassed. This option may only be used if the trigger is considered asynchronous and the destination has double sync input.
  {0x60+4j} TR_LEVEL_OUT[{j}] (j=0..15) — LEVEL Trigger out select register
    [31:24] SAR_RANGE_TR — Enable the selected SAR_RANGE output which are then ORed and routed to the associated trigger
    [13:12] DAC_FIFO_BELOW_THRESHOLD — Enable the selected DAC Fifo Below threshold of 3 to trigger a DMA transfer.
    [11:9] CMP_LOGIC_REMAP_TR — Enable the selected CMP Logic Remap output which are then ORed and routed to the associated trigger
    [8:0] CMP_TR — Enable the selected CMP outputs which are then ORed and routed to the associated trigger
  {0xA0+4j} TR_PULSE_OUT[{j}] (j=0..15) — PULSE Trigger out select register
    [3:0] SEL — Enable one of the available pulse trigger outputs for the associated trigger
      0=DISABLED (N/A); 1=SAR_ENTRY0_DONE (Entry results are ready for reading in the CHAN_RESULT registers); {v}=SAR_ENTRY{v-1}_DONE (N/A) (v=2..8); 9=SAR_FIR0_DONE (FIR results are ready for reading in the FIR_RESULT registers); 10=SAR_FIR1_DONE (N/A); 11=AC_TR (N/A); 12=HWFILT3P3Z0_STROBE (3P3Z Results are ready for reading in the 3P3Z_RESULT registers); 13=HWFILT3P3Z1_STROBE (N/A); 14=HWFILT3P3Z2_STROBE (N/A)
  0x100 FIFO group — FIFO Configuration
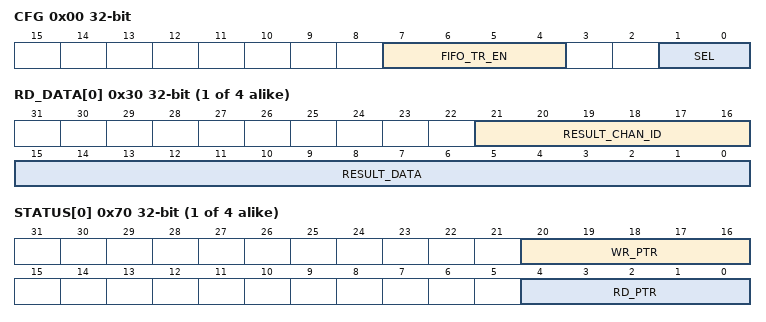
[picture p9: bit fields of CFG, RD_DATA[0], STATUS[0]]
    0x00 CFG — FIFO configuration register.
      [7:4] FIFO_TR_EN — Enable associated FIFO trigger
      [1:0] SEL
    0x04 CLR — FIFO FW clear register
      [3:0] CLR write-1-sets — Write a '1' to clear status for associated FIFO. This doesn't actually clear the data, it just resets the pointers. HW write a '1' to clear the bit when the reset is completed.
    {0x10+4k} LEVEL[{k}] (k=0..3) — FIFO level register.
      [4:0] LEVEL — FIFO level set. A trigger (and optional interrupt) event occurs when USED.USED = LEVEL+1.
    {0x30+4k} RD_DATA[{k}] (k=0..3) ro reset not defined — FIFO 32-bit read data register
      [21:16] RESULT_CHAN_ID — 6-bit Channel ID (upper bits), See SAR_CFG.CHAN_CFG.FIFO_SEL and SAR_CFG.FIR_CFG.FIFO_SEL registers to select a target FIFO. See SAR_CFG.CTRL.CHAN_ID_EN to optionally include a channel ID, otherwise these bits are 0
      [15:0] RESULT_DATA — 16-bit SAR/FIR result (lower bits). They are aligned as defined by SAR_CFG.CHAN_CFG.RIGHT_LEFT_ALIGN. See SAR_CFG.CHAN_CFG.FIFO_SEL and SAR_CFG.FIR_CFG.FIFO_SEL registers to select a target FIFO. See SAR_CFG.CTRL.CHAN_ID_EN to optionally include a channel ID, otherwise these bits are 0
    {0x50+4k} USED[{k}] (k=0..3) ro — FIFO used register
      [5:0] USED — Number of used/occupied entries in the FIFO.
    {0x70+4k} STATUS[{k}] (k=0..3) ro — FIFO status register
      [20:16] WR_PTR — FIFO write pointer: FIFO location at which a new data is written by the hardware. Note: This functionality is intended for debugging purposes.
      [4:0] RD_PTR — FIFO read pointer: FIFO location from which a data is read. Note: This functionality is intended for debugging purposes.
